# LRFDS2R register map
Vendor: Texas Instruments
Peripheral module from a debugger description file (folder CC27xxx7).
Registers are 32-bit, access per field, reset 0x0 unless marked. A register's access mark holds for its fields unless they carry their own. Offsets are as the file gives them; lines under a group give offsets from that group; [hi:lo] are bit positions; {n}, {i} and the like mark numbered series; 'fields as' and 'values as' point back to an identical list; <NAME> marks a mode.

## LRFDS2R
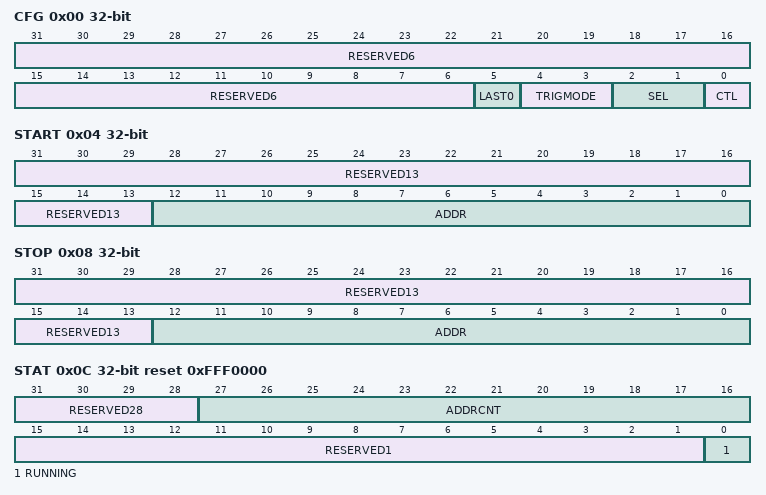
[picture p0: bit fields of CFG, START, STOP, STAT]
0x00 CFG — Internal. Only to be used through TI provided API.
  [31:6] RESERVED6 ro — Internal. Only to be used through TI provided API.
  [5] LAST0 rw — Internal. Only to be used through TI provided API.
    1=EN (Internal. Only to be used through TI provided API.); 0=DIS (Internal. Only to be used through TI provided API.)
  [4:3] TRIGMODE rw — Internal. Only to be used through TI provided API.
    2=ONEVENT (Internal. Only to be used through TI provided API.); 1=PERIODIC (Internal. Only to be used through TI provided API.); 0=ONESHOT (Internal. Only to be used through TI provided API.)
  [2:1] SEL rw — Internal. Only to be used through TI provided API.
    3=DECSTAGE (Internal. Only to be used through TI provided API.); 2=FRONTEND (Internal. Only to be used through TI provided API.); 1=ADCDIG (Internal. Only to be used through TI provided API.); 0=SYNTH (Internal. Only to be used through TI provided API.)
  [0] CTL rw — Internal. Only to be used through TI provided API.
    values as LAST0
0x04 START — Internal. Only to be used through TI provided API.
  [31:13] RESERVED13 ro — Internal. Only to be used through TI provided API.
  [12:0] ADDR rw — Internal. Only to be used through TI provided API.
    0x1FFF=ALLONES (Internal. Only to be used through TI provided API.); 0=ALLZEROS (Internal. Only to be used through TI provided API.)
0x08 STOP — Internal. Only to be used through TI provided API.
  fields as START
0x0C STAT ro reset 0xFFF0000 — Internal. Only to be used through TI provided API.
  [31:28] RESERVED28 — Internal. Only to be used through TI provided API.
  [27:16] ADDRCNT — Internal. Only to be used through TI provided API.
    0xFFF=ALLONES (Internal. Only to be used through TI provided API.); 0=ALLZEROS (Internal. Only to be used through TI provided API.)
  [15:1] RESERVED1 — Internal. Only to be used through TI provided API.
  [0] RUNNING — Internal. Only to be used through TI provided API.
    1=TRUE (Internal. Only to be used through TI provided API.); 0=FALSE (Internal. Only to be used through TI provided API.)
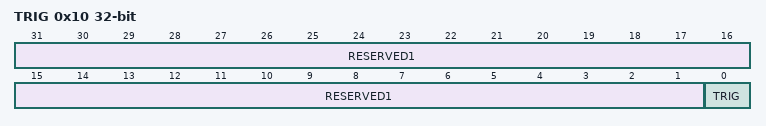
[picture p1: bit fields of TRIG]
0x10 TRIG — Internal. Only to be used through TI provided API.
  [31:1] RESERVED1 ro — Internal. Only to be used through TI provided API.
  [0] TRIG wo — Internal. Only to be used through TI provided API.
    1=ARM (Internal. Only to be used through TI provided API.); 0=NO_EFFECT (Internal. Only to be used through TI provided API.)
